CM_ "AUTOGENERATED FILE, DO NOT EDIT"
CM_ "Imported file _honda_2017.dbc starts here"
VERSION ""

NS_ :

BU_: EBCM ADAS PCM EPS VSA SCM BDY XXX EPB EON

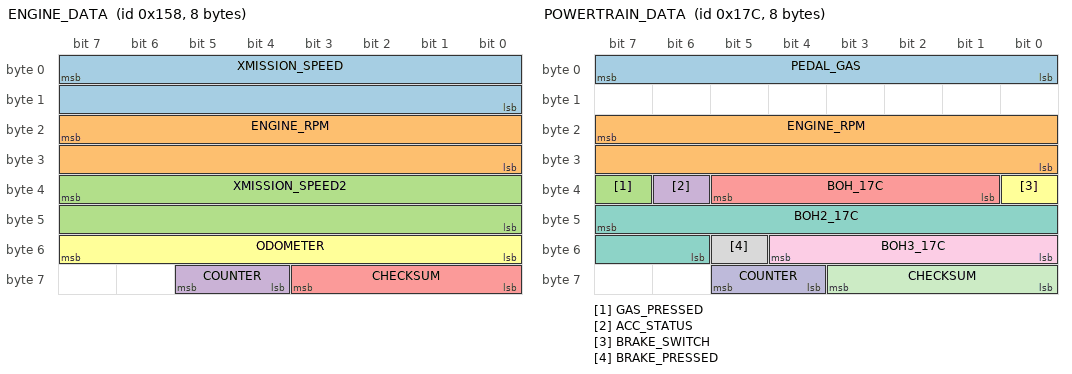
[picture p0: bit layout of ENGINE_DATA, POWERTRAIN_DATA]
BO_ 344 ENGINE_DATA: 8 PCM
 SG_ XMISSION_SPEED : 7|16@0+ (0.01,0) [0|250] "kph" EON
 SG_ ENGINE_RPM : 23|16@0+ (1,0) [0|15000] "rpm" EON
 SG_ XMISSION_SPEED2 : 39|16@0+ (0.01,0) [0|250] "kph" EON
 SG_ COUNTER : 61|2@0+ (1,0) [0|3] "" EON
 SG_ CHECKSUM : 59|4@0+ (1,0) [0|15] "" EON
 SG_ ODOMETER : 55|8@0+ (0.010588,0) [0|255] "km" XXX

BO_ 380 POWERTRAIN_DATA: 8 PCM
 SG_ PEDAL_GAS : 7|8@0+ (1,0) [0|255] "" EON
 SG_ ENGINE_RPM : 23|16@0+ (1,0) [0|15000] "rpm" EON
 SG_ GAS_PRESSED : 39|1@0+ (1,0) [0|1] "" EON
 SG_ ACC_STATUS : 38|1@0+ (1,0) [0|1] "rpm" EON
 SG_ BOH_17C : 37|5@0+ (1,0) [0|1] "rpm" EON
 SG_ BRAKE_SWITCH : 32|1@0+ (1,0) [0|1] "rpm" EON
 SG_ BOH2_17C : 47|10@0+ (1,0) [0|1] "rpm" EON
 SG_ BRAKE_PRESSED : 53|1@0+ (1,0) [0|1] "" EON
 SG_ BOH3_17C : 52|5@0+ (1,0) [0|1] "rpm" EON
 SG_ COUNTER : 61|2@0+ (1,0) [0|3] "" EON
 SG_ CHECKSUM : 59|4@0+ (1,0) [0|3] "" EON

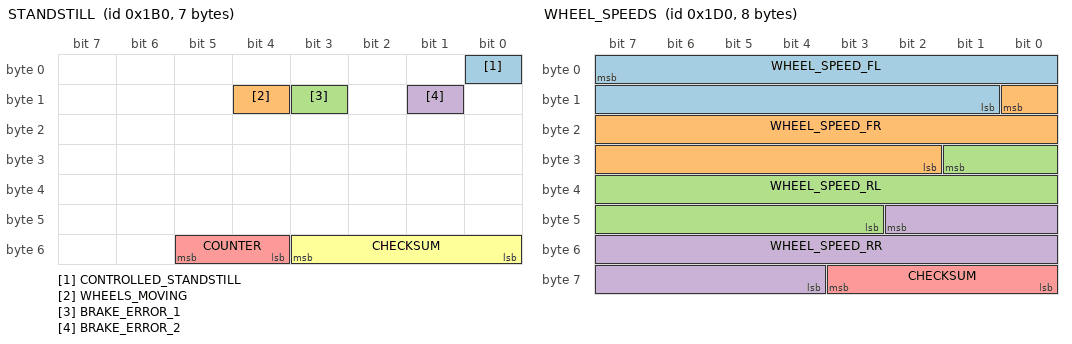
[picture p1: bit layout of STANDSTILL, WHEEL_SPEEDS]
BO_ 432 STANDSTILL: 7 VSA
 SG_ CONTROLLED_STANDSTILL : 0|1@0+ (1,0) [0|1] "" EON
 SG_ WHEELS_MOVING : 12|1@0+ (1,0) [0|1] "" EON
 SG_ BRAKE_ERROR_1 : 11|1@0+ (1,0) [0|1] "" EON
 SG_ BRAKE_ERROR_2 : 9|1@0+ (1,0) [0|1] "" EON
 SG_ COUNTER : 53|2@0+ (1,0) [0|3] "" EON
 SG_ CHECKSUM : 51|4@0+ (1,0) [0|3] "" EON

BO_ 464 WHEEL_SPEEDS: 8 VSA
 SG_ WHEEL_SPEED_FL : 7|15@0+ (0.01,0) [0|250] "kph" EON
 SG_ WHEEL_SPEED_FR : 8|15@0+ (0.01,0) [0|250] "kph" EON
 SG_ WHEEL_SPEED_RL : 25|15@0+ (0.01,0) [0|250] "kph" EON
 SG_ WHEEL_SPEED_RR : 42|15@0+ (0.01,0) [0|250] "kph" EON
 SG_ CHECKSUM : 59|4@0+ (1,0) [0|3] "" EON

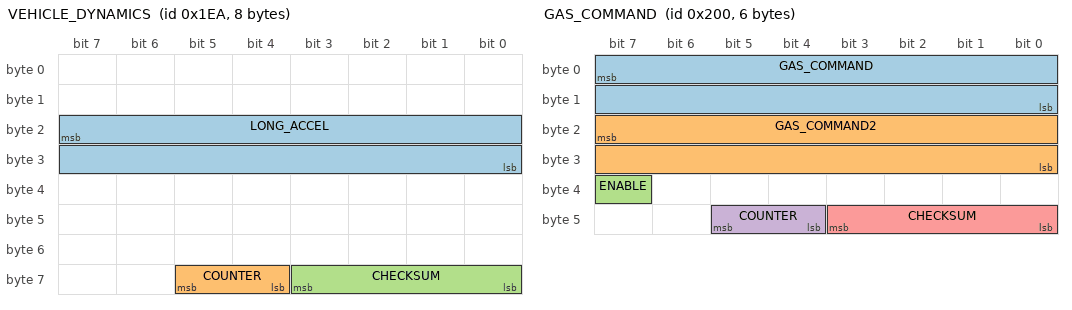
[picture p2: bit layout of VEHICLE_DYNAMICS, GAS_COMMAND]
BO_ 490 VEHICLE_DYNAMICS: 8 VSA
 SG_ LONG_ACCEL : 23|16@0- (0.0015384,0) [-20|20] "m/s2" EON
 SG_ COUNTER : 61|2@0+ (1,0) [0|3] "" EON
 SG_ CHECKSUM : 59|4@0+ (1,0) [0|3] "" EON

BO_ 506 BRAKE_COMMAND: 8 ADAS
 SG_ COMPUTER_BRAKE : 7|10@0+ (1,0) [0|1] "" EBCM
 SG_ ZEROS_BOH : 13|5@0+ (1,0) [0|1] "" EBCM
 SG_ COMPUTER_BRAKE_REQUEST : 8|1@0+ (1,0) [0|1] "" EBCM
 SG_ CRUISE_BOH2 : 23|3@0+ (1,0) [0|1] "" EBCM
 SG_ CRUISE_OVERRIDE : 20|1@0+ (1,0) [0|1] "" EBCM
 SG_ CRUISE_BOH3 : 19|1@0+ (1,0) [0|1] "" EBCM
 SG_ CRUISE_FAULT_CMD : 18|1@0+ (1,0) [0|1] "" EBCM
 SG_ CRUISE_CANCEL_CMD : 17|1@0+ (1,0) [0|1] "" EBCM
 SG_ COMPUTER_BRAKE_REQUEST_2 : 16|1@0+ (1,0) [0|1] "" EBCM
 SG_ SET_ME_0X80 : 31|8@0+ (1,0) [0|1] "" EBCM
 SG_ BRAKE_LIGHTS : 39|1@0+ (1,0) [0|1] "" EBCM
 SG_ CRUISE_STATES : 38|7@0+ (1,0) [0|1] "" EBCM
 SG_ CHIME : 47|3@0+ (1,0) [0|7] "" EBCM
 SG_ ZEROS_BOH6 : 44|1@0+ (1,0) [0|1] "" EBCM
 SG_ FCW : 43|2@0+ (1,0) [0|3] "" EBCM
 SG_ ZEROS_BOH4 : 55|8@0+ (1,0) [0|0] "" EBCM
 SG_ COUNTER : 61|2@0+ (1,0) [0|3] "" EBCM
 SG_ CHECKSUM : 59|4@0+ (1,0) [0|15] "" EBCM

BO_ 512 GAS_COMMAND: 6 EON
 SG_ GAS_COMMAND : 7|16@0+ (0.253984064,-83.3) [0|1] "" INTERCEPTOR
 SG_ GAS_COMMAND2 : 23|16@0+ (0.126992032,-83.3) [0|1] "" INTERCEPTOR
 SG_ ENABLE : 39|1@0+ (1,0) [0|1] "" INTERCEPTOR
 SG_ COUNTER : 45|2@0+ (1,0) [0|3] "" INTERCEPTOR
 SG_ CHECKSUM : 43|4@0+ (1,0) [0|3] "" INTERCEPTOR

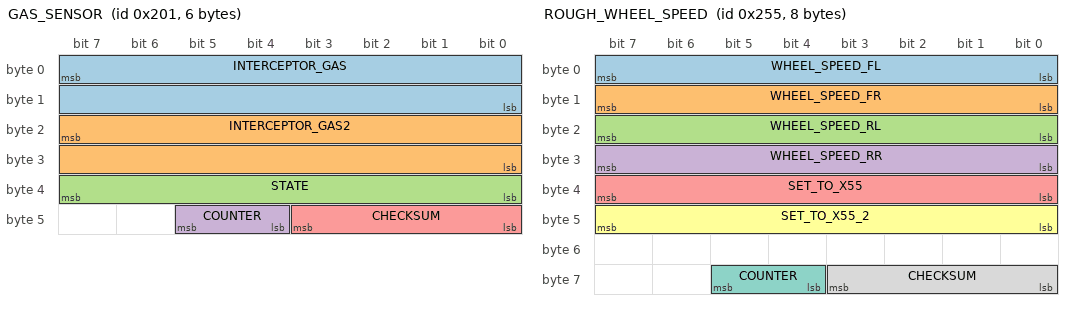
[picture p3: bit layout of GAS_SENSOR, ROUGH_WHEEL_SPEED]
BO_ 513 GAS_SENSOR: 6 INTERCEPTOR
 SG_ INTERCEPTOR_GAS : 7|16@0+ (0.253984064,-83.3) [0|1] "" EON
 SG_ INTERCEPTOR_GAS2 : 23|16@0+ (0.126992032,-83.3) [0|1] "" EON
 SG_ STATE : 39|8@0+ (1,0) [0|255] "" EON
 SG_ COUNTER : 45|2@0+ (1,0) [0|3] "" EON
 SG_ CHECKSUM : 43|4@0+ (1,0) [0|3] "" EON

BO_ 597 ROUGH_WHEEL_SPEED: 8 VSA
 SG_ WHEEL_SPEED_FL : 7|8@0+ (1,0) [0|255] "mph" EON
 SG_ WHEEL_SPEED_FR : 15|8@0+ (1,0) [0|255] "mph" EON
 SG_ WHEEL_SPEED_RL : 23|8@0+ (1,0) [0|255] "mph" EON
 SG_ WHEEL_SPEED_RR : 31|8@0+ (1,0) [0|255] "mph" EON
 SG_ SET_TO_X55 : 39|8@0+ (1,0) [0|255] "" EON
 SG_ SET_TO_X55_2 : 47|8@0+ (1,0) [0|255] "" EON
 SG_ COUNTER : 61|2@0+ (1,0) [0|3] "" EON
 SG_ CHECKSUM : 59|4@0+ (1,0) [0|15] "" EON

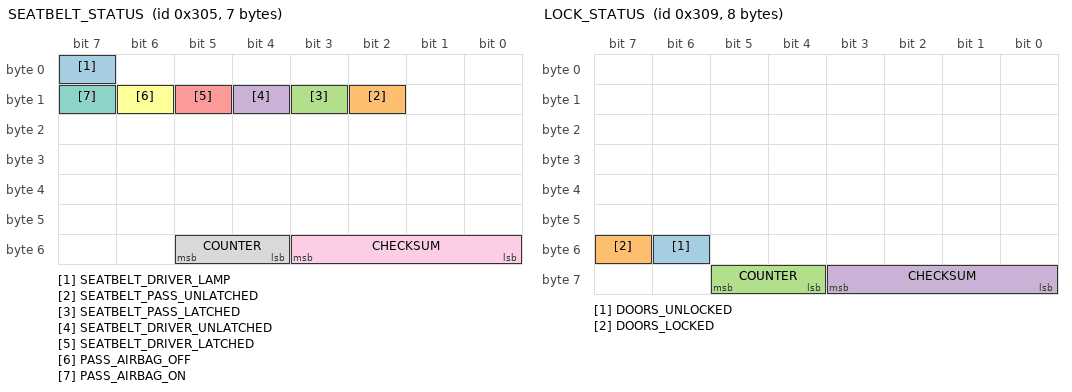
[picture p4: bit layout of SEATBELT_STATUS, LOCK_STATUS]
BO_ 773 SEATBELT_STATUS: 7 BDY
 SG_ SEATBELT_DRIVER_LAMP : 7|1@0+ (1,0) [0|1] "" EON
 SG_ SEATBELT_PASS_UNLATCHED : 10|1@0+ (1,0) [0|1] "" EON
 SG_ SEATBELT_PASS_LATCHED : 11|1@0+ (1,0) [0|1] "" EON
 SG_ SEATBELT_DRIVER_UNLATCHED : 12|1@0+ (1,0) [0|1] "" EON
 SG_ SEATBELT_DRIVER_LATCHED : 13|1@0+ (1,0) [0|1] "" EON
 SG_ PASS_AIRBAG_OFF : 14|1@0+ (1,0) [0|1] "" EON
 SG_ PASS_AIRBAG_ON : 15|1@0+ (1,0) [0|1] "" EON
 SG_ COUNTER : 53|2@0+ (1,0) [0|3] "" EON
 SG_ CHECKSUM : 51|4@0+ (1,0) [0|3] "" EON

BO_ 777 LOCK_STATUS: 8 XXX
 SG_ DOORS_UNLOCKED : 54|1@0+ (1,0) [0|1] "" EON
 SG_ DOORS_LOCKED : 55|1@0+ (1,0) [0|1] "" EON
 SG_ COUNTER : 61|2@0+ (1,0) [0|3] "" EON
 SG_ CHECKSUM : 59|4@0+ (1,0) [0|3] "" EON

BO_ 780 ACC_HUD: 8 ADAS
 SG_ PCM_SPEED : 7|16@0+ (0.01,0) [0|250] "kph" BDY
 SG_ PCM_GAS : 23|8@0+ (1,0) [0|127] "" BDY
 SG_ CRUISE_SPEED : 31|8@0+ (1,0) [0|255] "" BDY
 SG_ DTC_MODE : 39|1@0+ (1,0) [0|1] "" BDY
 SG_ BOH : 38|1@0+ (1,0) [0|1] "" BDY
 SG_ ACC_PROBLEM : 37|1@0+ (1,0) [0|1] "" BDY
 SG_ FCM_OFF : 36|1@0+ (1,0) [0|1] "" BDY
 SG_ BOH_2 : 35|1@0+ (1,0) [0|1] "" BDY
 SG_ FCM_PROBLEM : 34|1@0+ (1,0) [0|1] "" BDY
 SG_ RADAR_OBSTRUCTED : 33|1@0+ (1,0) [0|1] "" BDY
 SG_ ENABLE_MINI_CAR : 32|1@0+ (1,0) [0|1] "" BDY
 SG_ SET_ME_X03 : 47|2@0+ (1,0) [0|3] "" BDY
 SG_ HUD_LEAD : 45|2@0+ (1,0) [0|3] "" BDY
 SG_ BOH_3 : 43|1@0+ (1,0) [0|3] "" BDY
 SG_ BOH_4 : 42|1@0+ (1,0) [0|3] "" BDY
 SG_ BOH_5 : 41|1@0+ (1,0) [0|3] "" BDY
 SG_ CRUISE_CONTROL_LABEL : 40|1@0+ (1,0) [0|3] "" BDY
 SG_ HUD_DISTANCE_3 : 52|1@0+ (1,0) [0|1] "" BDY
 SG_ COUNTER : 61|2@0+ (1,0) [0|3] "" BDY
 SG_ CHECKSUM : 59|4@0+ (1,0) [0|3] "" BDY

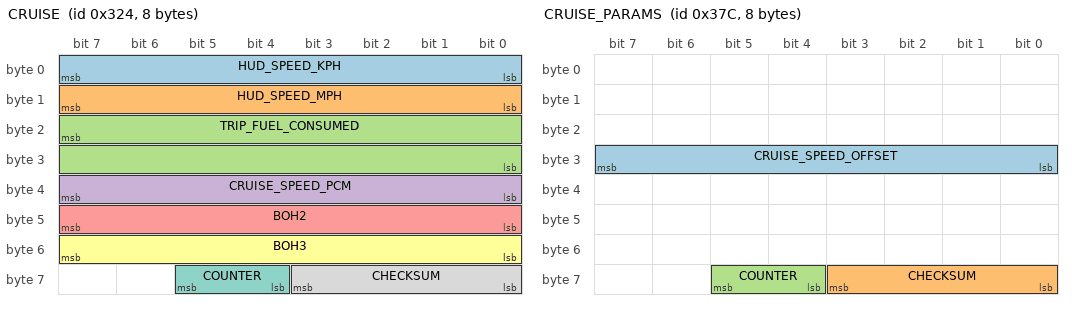
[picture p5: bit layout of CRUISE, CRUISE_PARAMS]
BO_ 804 CRUISE: 8 PCM
 SG_ HUD_SPEED_KPH : 7|8@0+ (1,0) [0|255] "kph" EON
 SG_ HUD_SPEED_MPH : 15|8@0+ (1,0) [0|255] "mph" EON
 SG_ TRIP_FUEL_CONSUMED : 23|16@0+ (1,0) [0|255] "" EON
 SG_ CRUISE_SPEED_PCM : 39|8@0+ (1,0) [0|255] "" EON
 SG_ BOH2 : 47|8@0- (1,0) [0|255] "" EON
 SG_ BOH3 : 55|8@0+ (1,0) [0|255] "" EON
 SG_ COUNTER : 61|2@0+ (1,0) [0|3] "" EON
 SG_ CHECKSUM : 59|4@0+ (1,0) [0|3] "" EON

BO_ 829 LKAS_HUD: 5 ADAS
 SG_ CAM_TEMP_HIGH : 7|1@0+ (1,0) [0|255] "" BDY
 SG_ SET_ME_X41 : 6|7@0+ (1,0) [0|127] "" BDY
 SG_ BOH : 6|7@0+ (1,0) [0|127] "" BDY
 SG_ DASHED_LANES : 14|1@0+ (1,0) [0|1] "" BDY
 SG_ DTC : 13|1@0+ (1,0) [0|1] "" BDY
 SG_ LKAS_PROBLEM : 12|1@0+ (1,0) [0|1] "" BDY
 SG_ LKAS_OFF : 11|1@0+ (1,0) [0|1] "" BDY
 SG_ SOLID_LANES : 10|1@0+ (1,0) [0|1] "" BDY
 SG_ LDW_RIGHT : 9|1@0+ (1,0) [0|1] "" BDY
 SG_ STEERING_REQUIRED : 8|1@0+ (1,0) [0|1] "" BDY
 SG_ BOH : 23|2@0+ (1,0) [0|4] "" BDY
 SG_ LDW_PROBLEM : 21|1@0+ (1,0) [0|1] "" BDY
 SG_ BEEP : 17|2@0+ (1,0) [0|1] "" BDY
 SG_ LDW_ON : 28|1@0+ (1,0) [0|1] "" BDY
 SG_ LDW_OFF : 27|1@0+ (1,0) [0|1] "" BDY
 SG_ CLEAN_WINDSHIELD : 26|1@0+ (1,0) [0|1] "" BDY
 SG_ SET_ME_X48 : 31|8@0+ (1,0) [0|255] "" BDY
 SG_ COUNTER : 37|2@0+ (1,0) [0|3] "" BDY
 SG_ CHECKSUM : 35|4@0+ (1,0) [0|15] "" BDY

BO_ 892 CRUISE_PARAMS: 8 PCM
 SG_ CRUISE_SPEED_OFFSET : 31|8@0- (0.1,0) [-128|127] "kph" EON
 SG_ CHECKSUM : 59|4@0+ (1,0) [0|3] "" EON
 SG_ COUNTER : 61|2@0+ (1,0) [0|3] "" EON

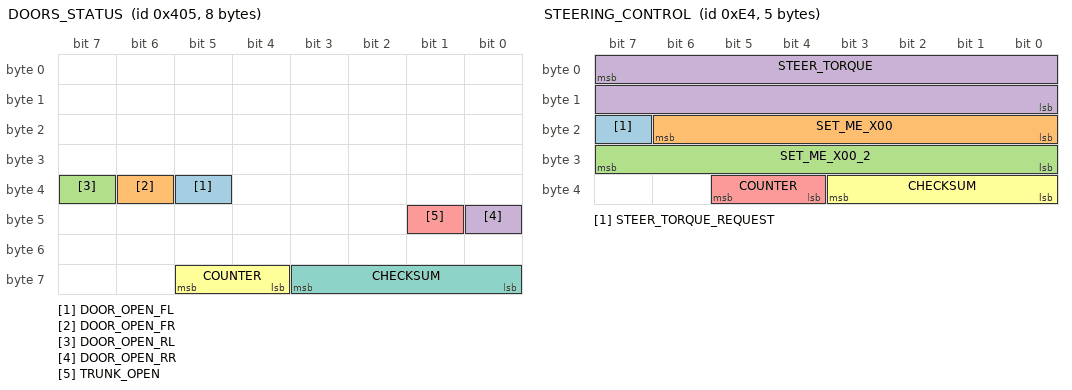
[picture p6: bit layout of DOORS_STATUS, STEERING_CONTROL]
BO_ 1029 DOORS_STATUS: 8 BDY
 SG_ DOOR_OPEN_FL : 37|1@0+ (1,0) [0|1] "" EON
 SG_ DOOR_OPEN_FR : 38|1@0+ (1,0) [0|1] "" EON
 SG_ DOOR_OPEN_RL : 39|1@0+ (1,0) [0|1] "" EON
 SG_ DOOR_OPEN_RR : 40|1@0+ (1,0) [0|1] "" EON
 SG_ TRUNK_OPEN : 41|1@0+ (1,0) [0|1] "" EON
 SG_ COUNTER : 61|2@0+ (1,0) [0|3] "" EON
 SG_ CHECKSUM : 59|4@0+ (1,0) [0|3] "" EON

CM_ SG_ 490 LONG_ACCEL "wheel speed derivative, noisy and zero snapping";
CM_ SG_ 773 PASS_AIRBAG_ON "Might just be indicator light";
CM_ SG_ 773 PASS_AIRBAG_OFF "Might just be indicator light";
CM_ SG_ 780 CRUISE_SPEED "255 = no speed";
CM_ SG_ 804 CRUISE_SPEED_PCM "255 = no speed";
CM_ SG_ 829 BEEP "beeps are pleasant, chimes are for warnngs etc...";

VAL_ 506 FCW 3 "fcw" 2 "fcw" 1 "fcw" 0 "no_fcw" ;
VAL_ 506 CHIME 4 "double_chime" 3 "single_chime" 2 "continuous_chime" 1 "repeating_chime" 0 "no_chime" ;
VAL_ 513 GAS_SENSOR 1 "fault" 0 "ready" ;
VAL_ 780 CRUISE_SPEED 255 "no_speed" 252 "stopped" ;
VAL_ 780 HUD_LEAD 3 "acc_off" 2 "solid_car" 1 "dashed_car" 0 "no_car" ;
VAL_ 829 BEEP 3 "single_beep" 2 "triple_beep" 1 "repeated_beep" 0 "no_beep" ;

CM_ "honda_civic_hatchback_ex_2017_can.dbc starts here"

BO_ 57 XXX_1: 3 XXX
 SG_ COUNTER : 21|2@0+ (1,0) [0|3] "" NEO
 SG_ CHECKSUM : 19|4@0+ (1,0) [0|15] "" NEO

BO_ 148 XXX_2: 8 XXX
 SG_ COUNTER : 61|2@0+ (1,0) [0|3] "" NEO
 SG_ CHECKSUM : 59|4@0+ (1,0) [0|15] "" NEO

BO_ 228 STEERING_CONTROL: 5 NEO
 SG_ STEER_TORQUE_REQUEST : 23|1@0+ (1,0) [0|1] "" EPS
 SG_ SET_ME_X00 : 22|7@0+ (1,0) [0|127] "" EPS
 SG_ SET_ME_X00_2 : 31|8@0+ (1,0) [0|0] "" EPS
 SG_ STEER_TORQUE : 7|16@0- (1,0) [-4096|4096] "" EPS
 SG_ COUNTER : 37|2@0+ (1,0) [0|3] "" EPS
 SG_ CHECKSUM : 35|4@0+ (1,0) [0|15] "" EPS

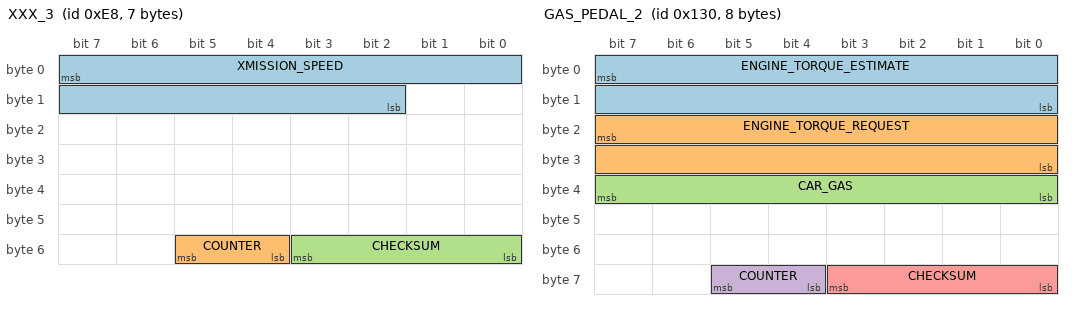
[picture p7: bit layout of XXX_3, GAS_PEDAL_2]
BO_ 232 XXX_3: 7 XXX
 SG_ XMISSION_SPEED : 7|14@0- (1,0) [1|0] "" XXX
 SG_ COUNTER : 53|2@0+ (1,0) [0|3] "" XXX
 SG_ CHECKSUM : 51|4@0+ (1,0) [0|15] "" XXX

BO_ 304 GAS_PEDAL_2: 8 PCM
 SG_ ENGINE_TORQUE_ESTIMATE : 7|16@0- (1,0) [-1000|1000] "Nm" NEO
 SG_ ENGINE_TORQUE_REQUEST : 23|16@0- (1,0) [-1000|1000] "Nm" NEO
 SG_ CAR_GAS : 39|8@0+ (1,0) [0|255] "" NEO
 SG_ COUNTER : 61|2@0+ (1,0) [0|3] "" NEO
 SG_ CHECKSUM : 59|4@0+ (1,0) [0|15] "" NEO

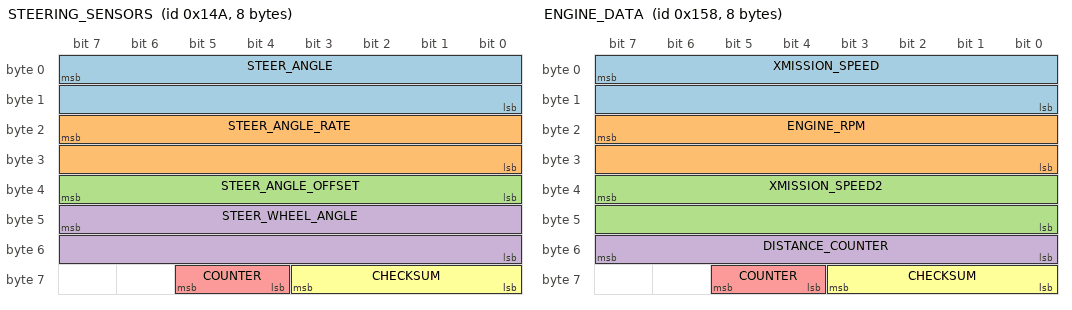
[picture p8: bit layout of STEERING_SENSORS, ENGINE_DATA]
BO_ 330 STEERING_SENSORS: 8 EPS
 SG_ STEER_ANGLE : 7|16@0- (-0.1,0) [-500|500] "deg" NEO
 SG_ STEER_ANGLE_RATE : 23|16@0- (-1,0) [-3000|3000] "deg/s" NEO
 SG_ STEER_ANGLE_OFFSET : 39|8@0- (-0.1,0) [-128|127] "deg" NEO
 SG_ STEER_WHEEL_ANGLE : 47|16@0- (-0.1,0) [-500|500] "deg" NEO
 SG_ COUNTER : 61|2@0+ (1,0) [0|3] "" NEO
 SG_ CHECKSUM : 59|4@0+ (1,0) [0|15] "" NEO

BO_ 340 XXX_4: 8 XXX
 SG_ COUNTER : 61|2@0+ (1,0) [0|3] "" NEO
 SG_ CHECKSUM : 59|4@0+ (1,0) [0|15] "" NEO

BO_ 344 ENGINE_DATA: 8 PCM
 SG_ XMISSION_SPEED : 7|16@0+ (0.01,0) [0|250] "kph" EON
 SG_ ENGINE_RPM : 23|16@0+ (1,0) [0|15000] "rpm" EON
 SG_ XMISSION_SPEED2 : 39|16@0+ (0.01,0) [0|250] "kph" EON
 SG_ DISTANCE_COUNTER : 55|8@0+ (10,0) [0|2550] "Meters" XXX
 SG_ COUNTER : 61|2@0+ (1,0) [0|3] "" NEO
 SG_ CHECKSUM : 59|4@0+ (1,0) [0|15] "" NEO

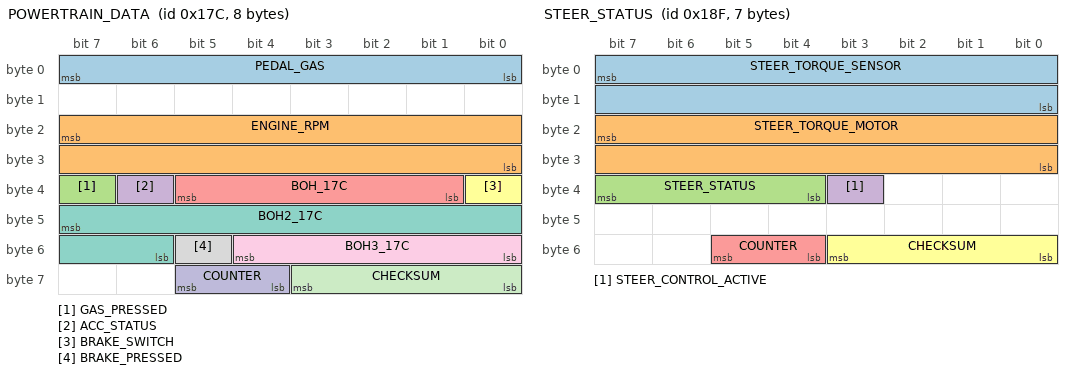
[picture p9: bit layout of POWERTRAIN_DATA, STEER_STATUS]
BO_ 380 POWERTRAIN_DATA: 8 PCM
 SG_ PEDAL_GAS : 7|8@0+ (1,0) [0|255] "" NEO
 SG_ ENGINE_RPM : 23|16@0+ (1,0) [0|15000] "rpm" NEO
 SG_ GAS_PRESSED : 39|1@0+ (1,0) [0|1] "" NEO
 SG_ ACC_STATUS : 38|1@0+ (1,0) [0|1] "" NEO
 SG_ BOH_17C : 37|5@0+ (1,0) [0|1] "" NEO
 SG_ BRAKE_SWITCH : 32|1@0+ (1,0) [0|1] "" NEO
 SG_ BOH2_17C : 47|10@0+ (1,0) [0|1] "" NEO
 SG_ BRAKE_PRESSED : 53|1@0+ (1,0) [0|1] "" NEO
 SG_ BOH3_17C : 52|5@0+ (1,0) [0|1] "" NEO
 SG_ COUNTER : 61|2@0+ (1,0) [0|3] "" NEO
 SG_ CHECKSUM : 59|4@0+ (1,0) [0|15] "" NEO

BO_ 399 STEER_STATUS: 7 EPS
 SG_ STEER_TORQUE_SENSOR : 7|16@0- (1,0) [-31000|31000] "tbd" NEO
 SG_ STEER_TORQUE_MOTOR : 23|16@0- (1,0) [-31000|31000] "tbd" NEO
 SG_ STEER_STATUS : 39|4@0+ (1,0) [0|15] "" NEO
 SG_ STEER_CONTROL_ACTIVE : 35|1@0+ (1,0) [0|1] "" NEO
 SG_ COUNTER : 53|2@0+ (1,0) [0|3] "" NEO
 SG_ CHECKSUM : 51|4@0+ (1,0) [0|15] "" NEO

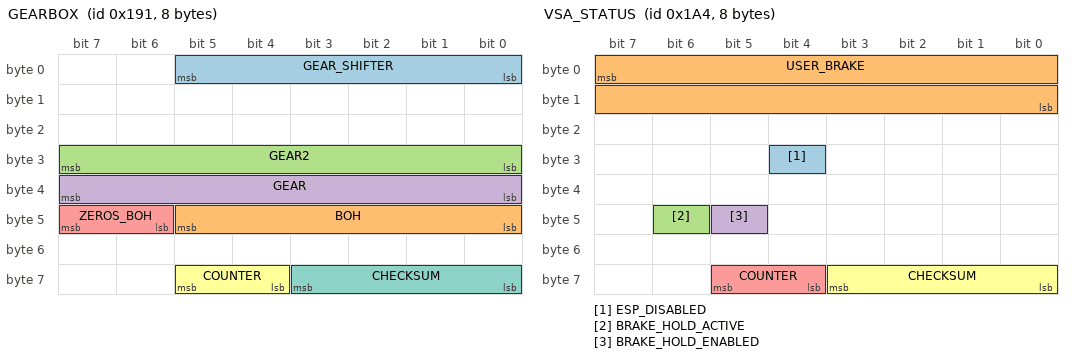
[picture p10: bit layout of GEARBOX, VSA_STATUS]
BO_ 401 GEARBOX: 8 PCM
 SG_ GEAR_SHIFTER : 5|6@0+ (1,0) [0|63] "" NEO
 SG_ BOH : 45|6@0+ (1,0) [0|63] "" XXX
 SG_ GEAR2 : 31|8@0+ (1,0) [0|1] "" XXX
 SG_ GEAR : 39|8@0+ (1,0) [0|255] "" XXX
 SG_ ZEROS_BOH : 47|2@0+ (1,0) [0|3] "" XXX
 SG_ COUNTER : 61|2@0+ (1,0) [0|3] "" NEO
 SG_ CHECKSUM : 59|4@0+ (1,0) [0|15] "" NEO

BO_ 420 VSA_STATUS: 8 VSA
 SG_ ESP_DISABLED : 28|1@0+ (1,0) [0|1] "" NEO
 SG_ USER_BRAKE : 7|16@0+ (0.015625,-103) [0|1000] "" NEO
 SG_ BRAKE_HOLD_ACTIVE : 46|1@0+ (1,0) [0|1] "" NEO
 SG_ BRAKE_HOLD_ENABLED : 45|1@0+ (1,0) [0|1] "" NEO
 SG_ COUNTER : 61|2@0+ (1,0) [0|3] "" NEO
 SG_ CHECKSUM : 59|4@0+ (1,0) [0|3] "" NEO

BO_ 427 XXX_5: 3 VSA
 SG_ COUNTER : 21|2@0+ (1,0) [0|3] "" XXX
 SG_ CHECKSUM : 19|4@0+ (1,0) [0|15] "" XXX

BO_ 428 XXX_6: 8 XXX
 SG_ COUNTER : 61|2@0+ (1,0) [0|3] "" XXX
 SG_ CHECKSUM : 59|4@0+ (1,0) [0|15] "" XXX

BO_ 441 XXX_7: 5 VSA
 SG_ COUNTER : 37|2@0+ (1,0) [0|3] "" XXX
 SG_ CHECKSUM : 35|4@0+ (1,0) [0|15] "" XXX

BO_ 446 XXX_8: 3 VSA
 SG_ COUNTER : 21|2@0+ (1,0) [0|3] "" XXX
 SG_ CHECKSUM : 19|4@0+ (1,0) [0|15] "" XXX

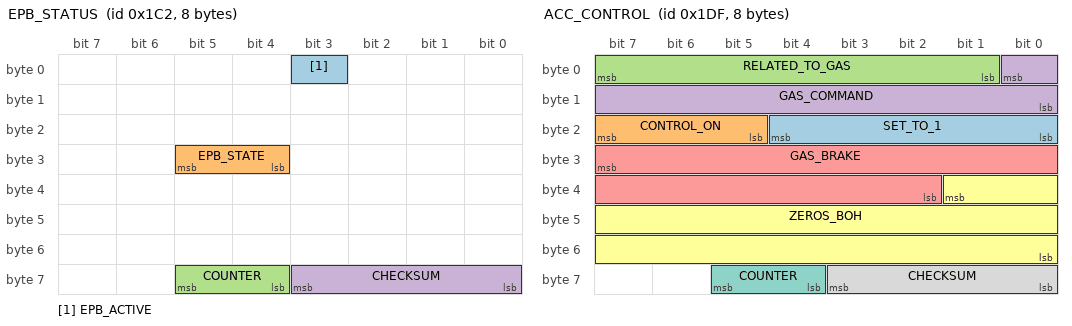
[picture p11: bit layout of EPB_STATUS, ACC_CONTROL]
BO_ 450 EPB_STATUS: 8 EPB
 SG_ EPB_ACTIVE : 3|1@0+ (1,0) [0|1] "" NEO
 SG_ EPB_STATE : 29|2@0+ (1,0) [0|3] "" NEO
 SG_ COUNTER : 61|2@0+ (1,0) [0|3] "" XXX
 SG_ CHECKSUM : 59|4@0+ (1,0) [0|15] "" XXX

BO_ 470 XXX_9: 2 XXX
 SG_ COUNTER : 13|2@0+ (1,0) [0|3] "" XXX
 SG_ CHECKSUM : 11|4@0+ (1,0) [0|15] "" XXX

BO_ 474 XXX_10: 8 XXX
 SG_ COUNTER : 61|2@0+ (1,0) [0|3] "" XXX
 SG_ CHECKSUM : 59|4@0+ (1,0) [0|15] "" XXX

BO_ 476 XXX_11: 7 XXX
 SG_ COUNTER : 53|2@0+ (1,0) [0|3] "" NEO
 SG_ CHECKSUM : 51|4@0+ (1,0) [0|15] "" NEO

BO_ 477 XXX_12: 8 XXX
 SG_ COUNTER : 61|2@0+ (1,0) [0|3] "" XXX
 SG_ CHECKSUM : 59|4@0+ (1,0) [0|15] "" XXX

BO_ 479 ACC_CONTROL: 8 NEO
 SG_ SET_TO_1 : 20|5@0+ (1,0) [0|1] "" PCM
 SG_ CONTROL_ON : 23|3@0+ (1,0) [0|5] "" XXX
 SG_ RELATED_TO_GAS : 7|7@0+ (1,0) [0|69] "" XXX
 SG_ GAS_COMMAND : 0|9@0+ (1,0) [0|1] "" PCM
 SG_ GAS_BRAKE : 31|14@0- (1,0) [0|1] "" XXX
 SG_ ZEROS_BOH : 33|18@0+ (1,0) [100|100] "" XXX
 SG_ COUNTER : 61|2@0+ (1,0) [0|3] "" XXX
 SG_ CHECKSUM : 59|4@0+ (1,0) [0|15] "" XXX

BO_ 490 XXX_13: 8 XXX
 SG_ COUNTER : 61|2@0+ (1,0) [0|3] "" XXX
 SG_ CHECKSUM : 59|4@0+ (1,0) [0|15] "" XXX

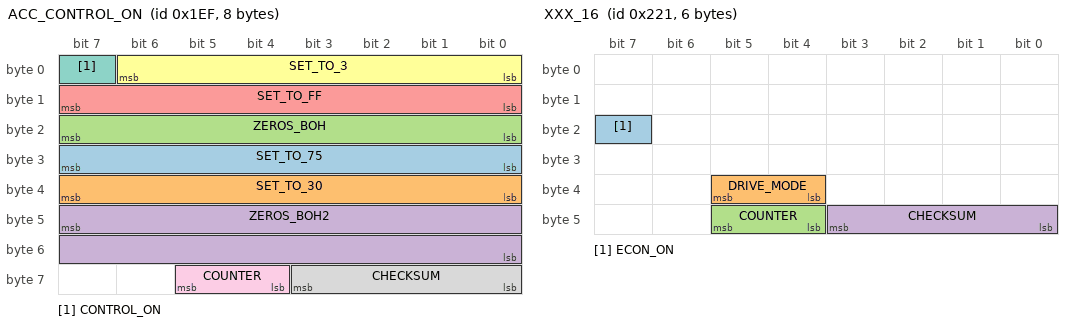
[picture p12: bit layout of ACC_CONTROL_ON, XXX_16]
BO_ 495 ACC_CONTROL_ON: 8 XXX
 SG_ SET_TO_75 : 31|8@0+ (1,0) [0|255] "" XXX
 SG_ SET_TO_30 : 39|8@0+ (1,0) [0|255] "" XXX
 SG_ ZEROS_BOH : 23|8@0+ (1,0) [0|255] "" XXX
 SG_ ZEROS_BOH2 : 47|16@0+ (1,0) [0|255] "" XXX
 SG_ SET_TO_FF : 15|8@0+ (1,0) [0|255] "" XXX
 SG_ SET_TO_3 : 6|7@0+ (1,0) [0|4095] "" XXX
 SG_ CONTROL_ON : 7|1@0+ (1,0) [0|1] "" XXX
 SG_ CHECKSUM : 59|4@0+ (1,0) [0|15] "" XXX
 SG_ COUNTER : 61|2@0+ (1,0) [0|3] "" XXX

BO_ 506 XXX_15: 8 XXX
 SG_ COUNTER : 61|2@0+ (1,0) [0|3] "" XXX
 SG_ CHECKSUM : 59|4@0+ (1,0) [0|15] "" XXX

BO_ 545 XXX_16: 6 SCM
 SG_ ECON_ON : 23|1@0+ (1,0) [0|1] "" XXX
 SG_ DRIVE_MODE : 37|2@0+ (1,0) [0|3] "" XXX
 SG_ COUNTER : 45|2@0+ (1,0) [0|3] "" BDY
 SG_ CHECKSUM : 43|4@0+ (1,0) [0|15] "" BDY

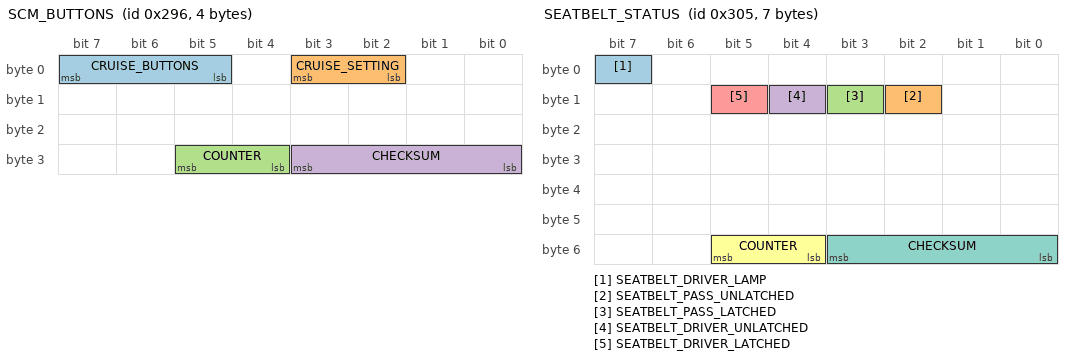
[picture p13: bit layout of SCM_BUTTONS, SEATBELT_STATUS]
BO_ 662 SCM_BUTTONS: 4 SCM
 SG_ CRUISE_BUTTONS : 7|3@0+ (1,0) [0|7] "" NEO
 SG_ CRUISE_SETTING : 3|2@0+ (1,0) [0|3] "" NEO
 SG_ COUNTER : 29|2@0+ (1,0) [0|3] "" NEO
 SG_ CHECKSUM : 27|4@0+ (1,0) [0|15] "" NEO

BO_ 773 SEATBELT_STATUS: 7 BDY
 SG_ SEATBELT_DRIVER_LAMP : 7|1@0+ (1,0) [0|1] "" NEO
 SG_ SEATBELT_PASS_UNLATCHED : 10|1@0+ (1,0) [0|1] "" NEO
 SG_ SEATBELT_PASS_LATCHED : 11|1@0+ (1,0) [0|1] "" NEO
 SG_ SEATBELT_DRIVER_UNLATCHED : 12|1@0+ (1,0) [0|1] "" NEO
 SG_ SEATBELT_DRIVER_LATCHED : 13|1@0+ (1,0) [0|1] "" NEO
 SG_ COUNTER : 53|2@0+ (1,0) [0|3] "" NEO
 SG_ CHECKSUM : 51|4@0+ (1,0) [0|15] "" NEO

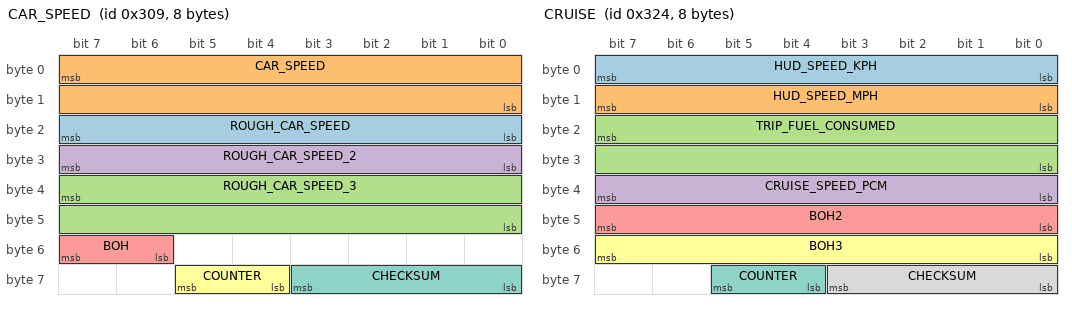
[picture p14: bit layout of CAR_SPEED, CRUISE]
BO_ 777 CAR_SPEED: 8 PCM
 SG_ ROUGH_CAR_SPEED : 23|8@0+ (1,0) [0|255] "" XXX
 SG_ CAR_SPEED : 7|16@0+ (1,0) [0|65535] "" XXX
 SG_ ROUGH_CAR_SPEED_3 : 39|16@0+ (1,0) [0|65535] "" XXX
 SG_ ROUGH_CAR_SPEED_2 : 31|8@0+ (1,0) [0|255] "" XXX
 SG_ BOH : 55|2@0+ (1,0) [0|255] "" XXX
 SG_ COUNTER : 61|2@0+ (1,0) [0|3] "" XXX
 SG_ CHECKSUM : 59|4@0+ (1,0) [0|15] "" XXX

BO_ 780 ACC_HUD: 8 ADAS
 SG_ CRUISE_SPEED : 31|8@0+ (1,0) [0|255] "" BDY
 SG_ DTC_MODE : 39|1@0+ (1,0) [0|1] "" BDY
 SG_ BOH : 38|1@0+ (1,0) [0|1] "" BDY
 SG_ FCM_PROBLEM : 34|1@0+ (1,0) [0|1] "" BDY
 SG_ RADAR_OBSTRUCTED : 33|1@0+ (1,0) [0|1] "" BDY
 SG_ ENABLE_MINI_CAR : 32|1@0+ (1,0) [0|1] "" BDY
 SG_ BOH_3 : 43|1@0+ (1,0) [0|3] "" BDY
 SG_ BOH_4 : 42|1@0+ (1,0) [0|3] "" BDY
 SG_ BOH_5 : 41|1@0+ (1,0) [0|3] "" BDY
 SG_ CRUISE_CONTROL_LABEL : 40|1@0+ (1,0) [0|3] "" BDY
 SG_ ZEROS_BOH : 7|24@0+ (0.002759506,0) [0|100] "m/s" BDY
 SG_ FCM_OFF : 35|1@0+ (1,0) [0|1] "" BDY
 SG_ SET_TO_1 : 36|1@0+ (1,0) [0|1] "" XXX
 SG_ HUD_DISTANCE : 47|2@0+ (1,0) [0|3] "" BDY
 SG_ HUD_LEAD : 45|2@0+ (1,0) [0|3] "" BDY
 SG_ ACC_PROBLEM : 37|1@0+ (1,0) [0|1] "" BDY
 SG_ ACC_ON : 52|1@0+ (1,0) [0|1] "" XXX
 SG_ BOH_6 : 51|4@0+ (1,0) [0|15] "" XXX
 SG_ SET_TO_X3 : 55|2@0+ (1,0) [0|3] "" XXX
 SG_ COUNTER : 61|2@0+ (1,0) [0|3] "" XXX
 SG_ CHECKSUM : 59|4@0+ (1,0) [0|15] "" XXX

BO_ 795 XXX_17: 8 XXX
 SG_ COUNTER : 61|2@0+ (1,0) [0|3] "" XXX
 SG_ CHECKSUM : 59|4@0+ (1,0) [0|15] "" XXX

BO_ 800 XXX_18: 8 XXX
 SG_ COUNTER : 61|2@0+ (1,0) [0|3] "" XXX
 SG_ CHECKSUM : 59|4@0+ (1,0) [0|15] "" XXX

BO_ 804 CRUISE: 8 PCM
 SG_ HUD_SPEED_KPH : 7|8@0+ (1,0) [0|255] "kph" NEO
 SG_ HUD_SPEED_MPH : 15|8@0+ (1,0) [0|255] "mph" NEO
 SG_ TRIP_FUEL_CONSUMED : 23|16@0+ (1,0) [0|255] "" NEO
 SG_ CRUISE_SPEED_PCM : 39|8@0+ (1,0) [0|255] "" NEO
 SG_ BOH2 : 47|8@0- (1,0) [0|255] "" NEO
 SG_ BOH3 : 55|8@0+ (1,0) [0|255] "" NEO
 SG_ COUNTER : 61|2@0+ (1,0) [0|3] "" NEO
 SG_ CHECKSUM : 59|4@0+ (1,0) [0|15] "" NEO

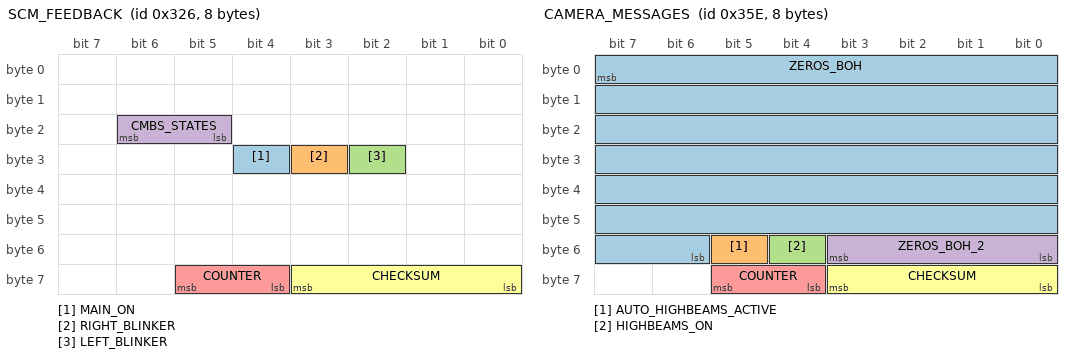
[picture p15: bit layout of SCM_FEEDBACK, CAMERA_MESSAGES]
BO_ 806 SCM_FEEDBACK: 8 SCM
 SG_ MAIN_ON : 28|1@0+ (1,0) [0|1] "" NEO
 SG_ RIGHT_BLINKER : 27|1@0+ (1,0) [0|1] "" NEO
 SG_ LEFT_BLINKER : 26|1@0+ (1,0) [0|1] "" NEO
 SG_ CMBS_STATES : 22|2@0+ (1,0) [0|3] "" NEO
 SG_ COUNTER : 61|2@0+ (1,0) [0|3] "" XXX
 SG_ CHECKSUM : 59|4@0+ (1,0) [0|15] "" XXX

BO_ 808 XXX_19: 8 XXX
 SG_ COUNTER : 61|2@0+ (1,0) [0|3] "" XXX
 SG_ CHECKSUM : 59|4@0+ (1,0) [0|15] "" XXX

BO_ 814 XXX_20: 4 XXX
 SG_ COUNTER : 29|2@0+ (1,0) [0|3] "" NEO
 SG_ CHECKSUM : 27|4@0+ (1,0) [0|15] "" NEO

BO_ 829 LKAS_HUD: 5 ADAS
 SG_ CAM_TEMP_HIGH : 7|1@0+ (1,0) [0|255] "" BDY
 SG_ BOH : 23|2@0+ (1,0) [0|4] "" BDY
 SG_ DASHED_LANES : 14|1@0+ (1,0) [0|1] "" BDY
 SG_ DTC : 13|1@0+ (1,0) [0|1] "" BDY
 SG_ LKAS_PROBLEM : 12|1@0+ (1,0) [0|1] "" BDY
 SG_ LKAS_OFF : 11|1@0+ (1,0) [0|1] "" BDY
 SG_ SOLID_LANES : 10|1@0+ (1,0) [0|1] "" BDY
 SG_ LDW_RIGHT : 9|1@0+ (1,0) [0|1] "" BDY
 SG_ STEERING_REQUIRED : 8|1@0+ (1,0) [0|1] "" BDY
 SG_ LDW_PROBLEM : 21|1@0+ (1,0) [0|1] "" BDY
 SG_ BEEP : 17|2@0+ (1,0) [0|1] "" BDY
 SG_ LDW_ON : 28|1@0+ (1,0) [0|1] "" BDY
 SG_ LDW_OFF : 27|1@0+ (1,0) [0|1] "" BDY
 SG_ CLEAN_WINDSHIELD : 26|1@0+ (1,0) [0|1] "" BDY
 SG_ SET_ME_X48 : 31|8@0+ (1,0) [0|255] "" BDY
 SG_ ZEROS_BOH : 6|6@0+ (1,0) [0|63] "" XXX
 SG_ SET_TO_1 : 0|1@0+ (1,0) [0|1] "" XXX
 SG_ BOH_2 : 15|1@0+ (1,0) [0|1] "" XXX
 SG_ SET_TO_ZERO : 20|3@0+ (1,0) [0|7] "" XXX
 SG_ COUNTER : 37|2@0+ (1,0) [0|3] "" BDY
 SG_ CHECKSUM : 35|4@0+ (1,0) [0|15] "" BDY

BO_ 862 CAMERA_MESSAGES: 8 CAM
 SG_ ZEROS_BOH : 7|50@0+ (1,0) [0|127] "" BDY
 SG_ AUTO_HIGHBEAMS_ACTIVE : 53|1@0+ (1,0) [0|1] "" XXX
 SG_ HIGHBEAMS_ON : 52|1@0+ (1,0) [0|1] "" XXX
 SG_ ZEROS_BOH_2 : 48|4@1+ (1,0) [0|15] "" XXX
 SG_ COUNTER : 61|2@0+ (1,0) [0|3] "" XXX
 SG_ CHECKSUM : 59|4@0+ (1,0) [0|15] "" XXX

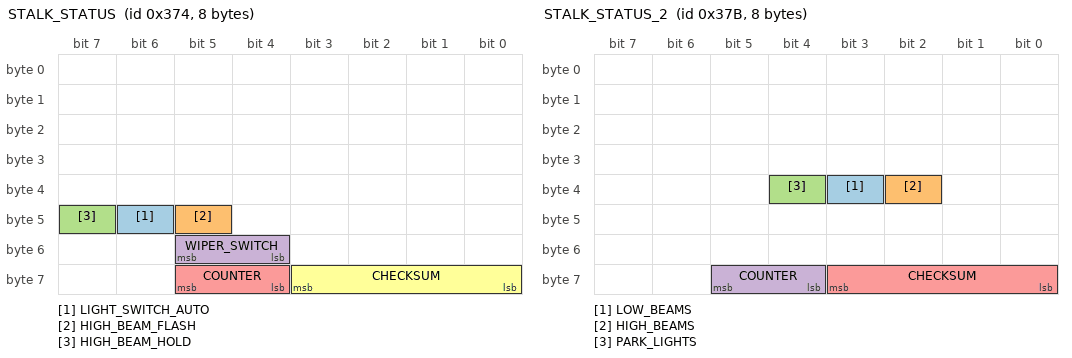
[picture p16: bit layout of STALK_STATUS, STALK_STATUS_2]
BO_ 884 STALK_STATUS: 8 XXX
 SG_ LIGHT_SWITCH_AUTO : 46|1@0+ (1,0) [0|1] "" XXX
 SG_ HIGH_BEAM_FLASH : 45|1@0+ (1,0) [0|1] "" XXX
 SG_ HIGH_BEAM_HOLD : 47|1@0+ (1,0) [0|1] "" XXX
 SG_ WIPER_SWITCH : 53|2@0+ (1,0) [0|3] "" XXX
 SG_ COUNTER : 61|2@0+ (1,0) [0|3] "" XXX
 SG_ CHECKSUM : 59|4@0+ (1,0) [0|15] "" XXX

BO_ 891 STALK_STATUS_2: 8 XXX
 SG_ LOW_BEAMS : 35|1@0+ (1,0) [0|1] "" XXX
 SG_ HIGH_BEAMS : 34|1@0+ (1,0) [0|1] "" XXX
 SG_ PARK_LIGHTS : 36|1@0+ (1,0) [0|1] "" XXX
 SG_ COUNTER : 61|2@0+ (1,0) [0|3] "" XXX
 SG_ CHECKSUM : 59|4@0+ (1,0) [0|15] "" XXX

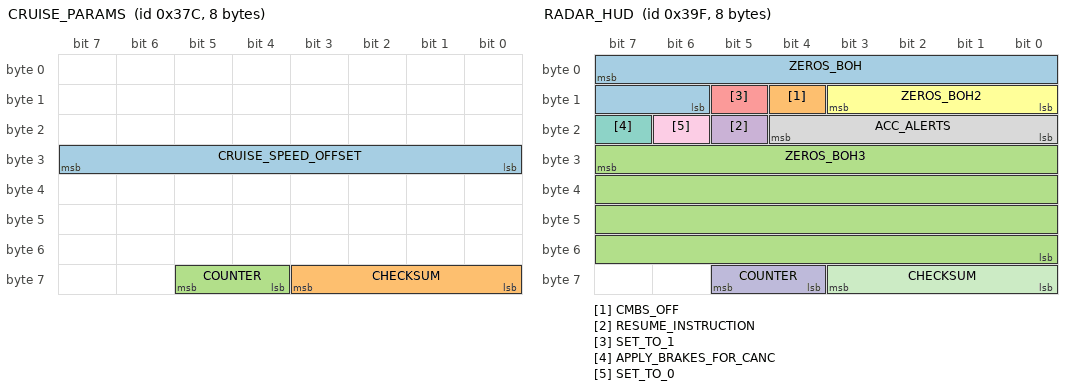
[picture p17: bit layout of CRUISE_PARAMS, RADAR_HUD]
BO_ 892 CRUISE_PARAMS: 8 PCM
 SG_ CRUISE_SPEED_OFFSET : 31|8@0- (0.1,0) [-128|127] "kph" NEO
 SG_ CHECKSUM : 59|4@0+ (1,0) [0|3] "" NEO
 SG_ COUNTER : 61|2@0+ (1,0) [0|15] "" NEO

BO_ 927 RADAR_HUD: 8 RADAR
 SG_ ZEROS_BOH : 7|10@0+ (1,0) [0|127] "" BDY
 SG_ CMBS_OFF : 12|1@0+ (1,0) [0|1] "" BDY
 SG_ ZEROS_BOH3 : 31|32@0+ (1,0) [0|4294967295] "" XXX
 SG_ RESUME_INSTRUCTION : 21|1@0+ (1,0) [0|1] "" XXX
 SG_ SET_TO_1 : 13|1@0+ (1,0) [0|1] "" BDY
 SG_ ZEROS_BOH2 : 11|4@0+ (1,0) [0|1] "" XXX
 SG_ APPLY_BRAKES_FOR_CANC : 23|1@0+ (1,0) [0|1] "" XXX
 SG_ ACC_ALERTS : 20|5@0+ (1,0) [0|1] "" BDY
 SG_ SET_TO_0 : 22|1@0+ (1,0) [0|1] "" XXX
 SG_ COUNTER : 61|2@0+ (1,0) [0|3] "" XXX
 SG_ CHECKSUM : 59|4@0+ (1,0) [0|15] "" XXX

BO_ 929 XXX_21: 8 XXX
 SG_ COUNTER : 61|2@0+ (1,0) [0|3] "" XXX
 SG_ CHECKSUM : 59|4@0+ (1,0) [0|15] "" XXX

BO_ 985 XXX_22: 3 XXX
 SG_ COUNTER : 21|2@0+ (1,0) [0|3] "" XXX
 SG_ CHECKSUM : 19|4@0+ (1,0) [0|15] "" XXX

BO_ 1024 XXX_23: 5 XXX
 SG_ COUNTER : 37|2@0+ (1,0) [0|3] "" XXX
 SG_ CHECKSUM : 35|4@0+ (1,0) [0|15] "" XXX

BO_ 1027 XXX_24: 5 XXX
 SG_ COUNTER : 37|2@0+ (1,0) [0|3] "" XXX
 SG_ CHECKSUM : 35|4@0+ (1,0) [0|15] "" XXX

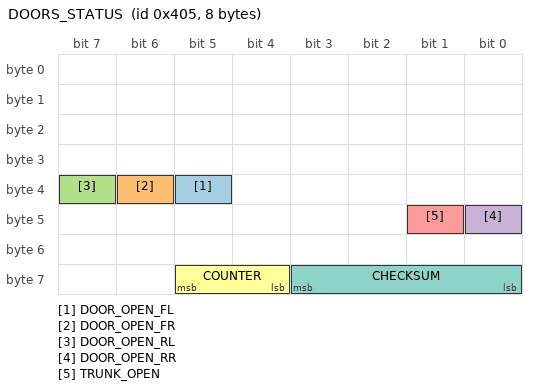
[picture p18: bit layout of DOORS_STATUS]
BO_ 1029 DOORS_STATUS: 8 BDY
 SG_ DOOR_OPEN_FL : 37|1@0+ (1,0) [0|1] "" NEO
 SG_ DOOR_OPEN_FR : 38|1@0+ (1,0) [0|1] "" NEO
 SG_ DOOR_OPEN_RL : 39|1@0+ (1,0) [0|1] "" NEO
 SG_ DOOR_OPEN_RR : 40|1@0+ (1,0) [0|1] "" NEO
 SG_ TRUNK_OPEN : 41|1@0+ (1,0) [0|1] "" NEO
 SG_ COUNTER : 61|2@0+ (1,0) [0|3] "" NEO
 SG_ CHECKSUM : 59|4@0+ (1,0) [0|15] "" NEO

BO_ 1036 XXX_25: 8 XXX
 SG_ COUNTER : 61|2@0+ (1,0) [0|3] "" XXX
 SG_ CHECKSUM : 59|4@0+ (1,0) [0|15] "" XXX

BO_ 1039 XXX_26: 8 XXX
 SG_ COUNTER : 61|2@0+ (1,0) [0|3] "" XXX
 SG_ CHECKSUM : 59|4@0+ (1,0) [0|15] "" XXX

BO_ 1108 XXX_27: 8 XXX
 SG_ COUNTER : 61|2@0+ (1,0) [0|3] "" XXX
 SG_ CHECKSUM : 59|4@0+ (1,0) [0|15] "" XXX

BO_ 1302 XXX_28: 8 XXX
 SG_ COUNTER : 61|2@0+ (1,0) [0|3] "" XXX
 SG_ CHECKSUM : 59|4@0+ (1,0) [0|15] "" XXX

BO_ 1322 XXX_29: 5 XXX
 SG_ COUNTER : 37|2@0+ (1,0) [0|3] "" XXX
 SG_ CHECKSUM : 35|4@0+ (1,0) [0|15] "" XXX

BO_ 1361 XXX_30: 5 XXX
 SG_ COUNTER : 37|2@0+ (1,0) [0|3] "" XXX
 SG_ CHECKSUM : 35|4@0+ (1,0) [0|15] "" XXX

BO_ 1365 XXX_31: 5 XXX
 SG_ COUNTER : 37|2@0+ (1,0) [0|3] "" XXX
 SG_ CHECKSUM : 35|4@0+ (1,0) [0|15] "" XXX

BO_ 1424 XXX_32: 5 XXX
 SG_ COUNTER : 37|2@0+ (1,0) [0|3] "" XXX
 SG_ CHECKSUM : 35|4@0+ (1,0) [0|15] "" XXX

BO_ 1600 XXX_33: 5 XXX
 SG_ COUNTER : 37|2@0+ (1,0) [0|3] "" XXX
 SG_ CHECKSUM : 35|4@0+ (1,0) [0|15] "" XXX

BO_ 1601 XXX_34: 8 XXX
 SG_ COUNTER : 61|2@0+ (1,0) [0|3] "" XXX
 SG_ CHECKSUM : 59|4@0+ (1,0) [0|15] "" XXX

BO_ 1618 XXX_35: 5 XXX
 SG_ COUNTER : 37|2@0+ (1,0) [0|3] "" XXX
 SG_ CHECKSUM : 35|4@0+ (1,0) [0|15] "" XXX

BO_ 1633 XXX_36: 8 XXX
 SG_ COUNTER : 61|2@0+ (1,0) [0|3] "" XXX
 SG_ CHECKSUM : 59|4@0+ (1,0) [0|15] "" XXX

BO_ 1670 XXX_37: 5 XXX
 SG_ COUNTER : 37|2@0+ (1,0) [0|3] "" XXX
 SG_ CHECKSUM : 35|4@0+ (1,0) [0|15] "" XXX

CM_ SG_ 450 EPB_STATE "3: On, 2: Disengaging, 1: Engaging, 0: Off";
CM_ SG_ 479 CONTROL_ON "Set to 5 when car is being controlled";
CM_ SG_ 479 RELATED_TO_GAS "bits 7, 3, and 1 set to 1 when gas not applied";
CM_ SG_ 479 GAS_BRAKE "Signed value, negative when braking and positive when applying gas";
CM_ SG_ 479 ZEROS_BOH "Signed value, negative when braking, positive when applying gas";
CM_ SG_ 780 HUD_LEAD "0: blank, 1:  no car, 2: car, 3: ACC Off";
CM_ SG_ 780 CRUISE_SPEED 255 "no_speed" 252 "stopped" ;
CM_ SG_ 806 CMBS_STATES "3: Pressed, 2: On, 0: Off";
CM_ SG_ 884 WIPER_SWITCH "0 = PARKED, 1 = INTERMITTENT, 2 = LOW, 3 = HIGH/QUICK WIPE";
CM_ SG_ 891 HIGH_BEAMS "FLASH TO PASS OR FULL ON";

CM_ "CHFFR_METRIC 330 STEER_ANGLE STEER_ANGLE 0.36 180; CHFFR_METRIC 380 ENGINE_RPM ENGINE_RPM 1 0; CHFFR_METRIC 804 ENGINE_TEMPERATURE ENGINE_TEMPERATURE 1 0";
